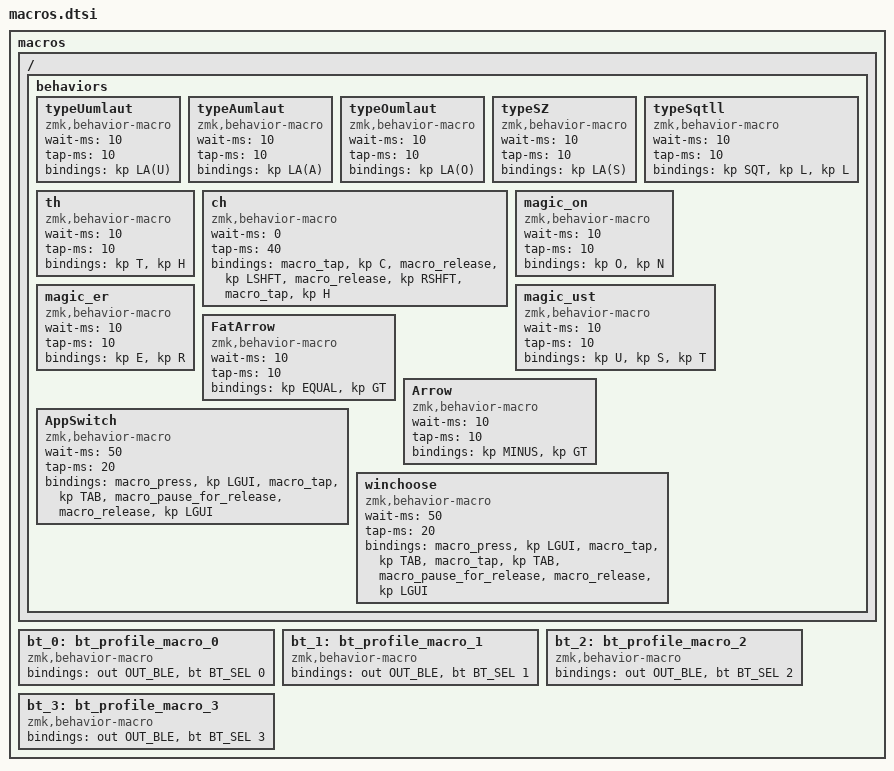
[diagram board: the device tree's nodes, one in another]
 macros {

    ZMK_MACRO(typeUumlaut,
        wait-ms = <10>;
        tap-ms =  <10>;
        bindings = <&kp LA(U)>;
    )
    ZMK_MACRO(typeAumlaut,
        wait-ms = <10>;
        tap-ms =  <10>;
        bindings = <&kp LA(A)>;
    )
    ZMK_MACRO(typeOumlaut,
        wait-ms = <10>;
        tap-ms =  <10>;
        bindings = <&kp LA(O)>;
    )
    ZMK_MACRO(typeSZ,
        wait-ms = <10>;
        tap-ms =  <10>;
        bindings = <&kp LA(S)>;
    )
    ZMK_MACRO(typeSqtll,
        wait-ms = <10>;
        tap-ms =  <10>;
        bindings = <&kp SQT>
                 , <&kp L>
                 , <&kp L>;
    )

    ZMK_MACRO(th,
        wait-ms = <10>;
        tap-ms =  <10>;
        bindings = <&kp T>
                //  , <&macro_release &kp LSHFT>
                //  , <&macro_release &kp RSHFT>
                    , <&kp H>;
    )
    ZMK_MACRO(ch,
        wait-ms = <0>;
        tap-ms = <40>;
        bindings = <&macro_tap &kp C>
            , <&macro_release &kp LSHFT>
            , <&macro_release &kp RSHFT>
            , <&macro_tap &kp H>
            ;
    )

    ZMK_MACRO(magic_on,
        wait-ms = <10>;
        tap-ms = <10>;
        bindings = <&kp O>
                , <&kp N>;
    )
    ZMK_MACRO(magic_ust,
        wait-ms = <10>;
        tap-ms = <10>;
        bindings = <&kp U>
                , <&kp S>
                , <&kp T>;
    )
    ZMK_MACRO(magic_er,
        wait-ms = <10>;
        tap-ms = <10>;
        bindings = <&kp E>
                , <&kp R>;
    )

    ZMK_MACRO(FatArrow,
        wait-ms  = <10>;
        tap-ms   = <10>;
        bindings = <&kp EQUAL>
                , <&kp GT>;
    )

    ZMK_MACRO(Arrow,
        wait-ms = <10>;
        tap-ms = <10>;
        bindings = <&kp MINUS>
                , <&kp GT>;
    )
    bt_0: bt_profile_macro_0 {
        compatible = "zmk,behavior-macro";
        #binding-cells = <0>;
        bindings
            = <&out OUT_BLE>,
                <&bt BT_SEL 0>;
    };

    bt_1: bt_profile_macro_1 {
        compatible = "zmk,behavior-macro";
        #binding-cells = <0>;
        bindings
            = <&out OUT_BLE>,
                <&bt BT_SEL 1>;
    };

    bt_2: bt_profile_macro_2 {
        compatible = "zmk,behavior-macro";
        #binding-cells = <0>;
        bindings
            = <&out OUT_BLE>,
                <&bt BT_SEL 2>;
    };

    bt_3: bt_profile_macro_3 {
        compatible = "zmk,behavior-macro";
        #binding-cells = <0>;
        bindings
            = <&out OUT_BLE>,
                <&bt BT_SEL 3>;
    };

    ZMK_MACRO(AppSwitch,
        wait-ms = <50>;
        tap-ms = <20>;
        bindings  = <&macro_press &kp LGUI>
                    , <&macro_tap &kp TAB>
                    , <&macro_pause_for_release>
                    , <&macro_release &kp LGUI>
        ;
    )
    ZMK_MACRO(winchoose,
        wait-ms = <50>;
        tap-ms = <20>;
        bindings  = <&macro_press &kp LGUI>
                    , <&macro_tap &kp TAB>
                    , <&macro_tap &kp TAB>
                    , <&macro_pause_for_release>
                    , <&macro_release &kp LGUI>
        ;
    )
};
